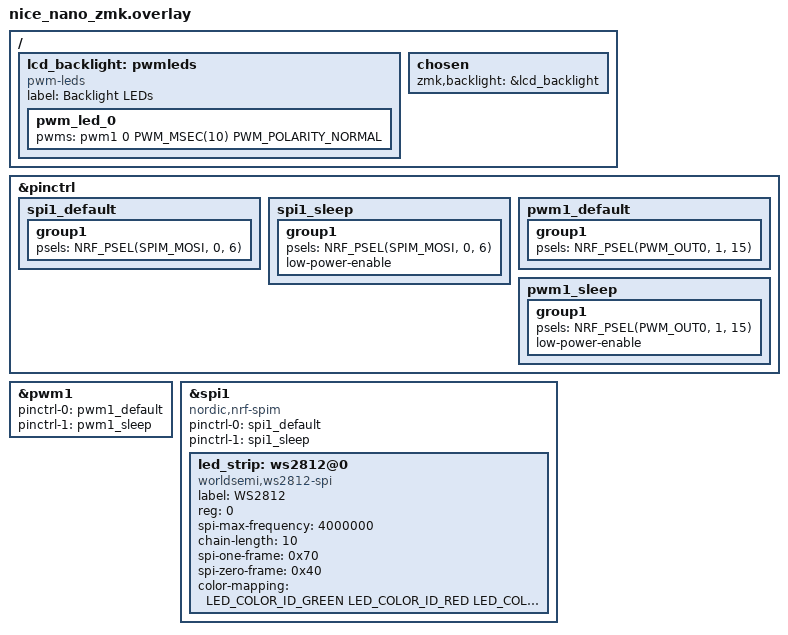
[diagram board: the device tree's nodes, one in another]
/**
 * Generated by Shield Wizard for ZMK
 * Applies to shield "melior_central_snake" with board "nice_nano" only
 */

#include <dt-bindings/led/led.h>

&pinctrl {
	spi1_default: spi1_default {
		group1 {
			psels = <NRF_PSEL(SPIM_MOSI, 0, 6)>;
		};
	};

	spi1_sleep: spi1_sleep {
		group1 {
			psels = <NRF_PSEL(SPIM_MOSI, 0, 6)>;
			low-power-enable;
		};
	};

	pwm1_default: pwm1_default {
        group1 {
            psels = <NRF_PSEL(PWM_OUT0, 1, 15)>;
        };
    };

    pwm1_sleep: pwm1_sleep {
        group1 {
            psels = <NRF_PSEL(PWM_OUT0, 1, 15)>;
            low-power-enable;
        };
    };
};

/ {
    lcd_backlight: pwmleds {
        compatible = "pwm-leds";
        label = "Backlight LEDs";
        pwm_led_0: pwm_led_0 {
            pwms = <&pwm1 0 PWM_MSEC(10) PWM_POLARITY_NORMAL>;
        };
    };
};

/* Enable the PWM hardware */
&pwm1 {
    status = "okay";
    pinctrl-0 = <&pwm1_default>;
    pinctrl-1 = <&pwm1_sleep>;
    pinctrl-names = "default", "sleep";
};

&spi1 {
	compatible = "nordic,nrf-spim";
	status = "okay";

	pinctrl-0 = <&spi1_default>;
	pinctrl-1 = <&spi1_sleep>;
	pinctrl-names = "default", "sleep";

	led_strip: ws2812@0 {
		compatible = "worldsemi,ws2812-spi";
		label = "WS2812";

		/* SPI */
		reg = <0>; /* ignored, but necessary for SPI bindings */
		spi-max-frequency = <4000000>;

		/* WS2812 */
		chain-length = <10>; /* arbitrary; change at will */
		spi-one-frame = <0x70>;
		spi-zero-frame = <0x40>;

		color-mapping = <LED_COLOR_ID_GREEN LED_COLOR_ID_RED LED_COLOR_ID_BLUE>;
	};
};

/ {
	chosen {
        zmk,backlight = &lcd_backlight;
	};
};




